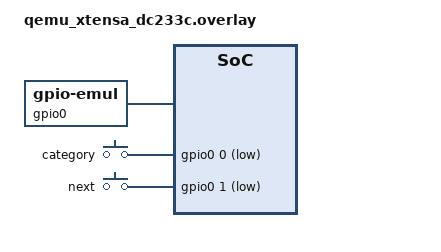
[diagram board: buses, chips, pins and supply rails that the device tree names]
/* qemu build. */

#include <zephyr/dt-bindings/gpio/gpio.h>
#include <zephyr/dt-bindings/input/input-event-codes.h>

/ {
    aliases {
        kveld-category = &kveld_category;
        kveld-next = &kveld_next;
    };

    gpio0: gpio_emul {
        compatible = "zephyr,gpio-emul";
        gpio-controller;
        #gpio-cells = <2>;
        ngpios = <32>;
        rising-edge;
        falling-edge;
        high-level;
        low-level;
    };

    kveld_buttons: kveld-buttons {
        compatible = "gpio-keys";
        debounce-interval-ms = <30>;
        kveld_category: category {
            gpios = <&gpio0 0 GPIO_ACTIVE_LOW>;
            zephyr,code = <INPUT_KEY_MENU>;
            label = "category";
        };
        kveld_next: next {
            gpios = <&gpio0 1 GPIO_ACTIVE_LOW>;
            zephyr,code = <INPUT_KEY_ENTER>;
            label = "next";
        };
    };

    /* A dummy panel the size of the real one. */
    kveld_dummy: dummy_dc {
        compatible = "zephyr,dummy-dc";
        width = <250>;
        height = <122>;
        status = "okay";
    };

    chosen {
        zephyr,display = &kveld_dummy;
    };
};
